# STM32WB30_CM4 register map
File version: 1.3
CPU: CM4 r0p1, little endian, MPU, FPU, 4 interrupt priority bits
Registers are 32-bit, read-write, reset 0x0 unless marked. A register's access mark holds for its fields unless they carry their own. Offsets are from the block's base; [hi:lo] are bit positions; {n}, {i} and the like mark numbered series; 'fields as' and 'values as' point back to an identical list.

## DBGMCU — Debug support
Base 0xE0042000
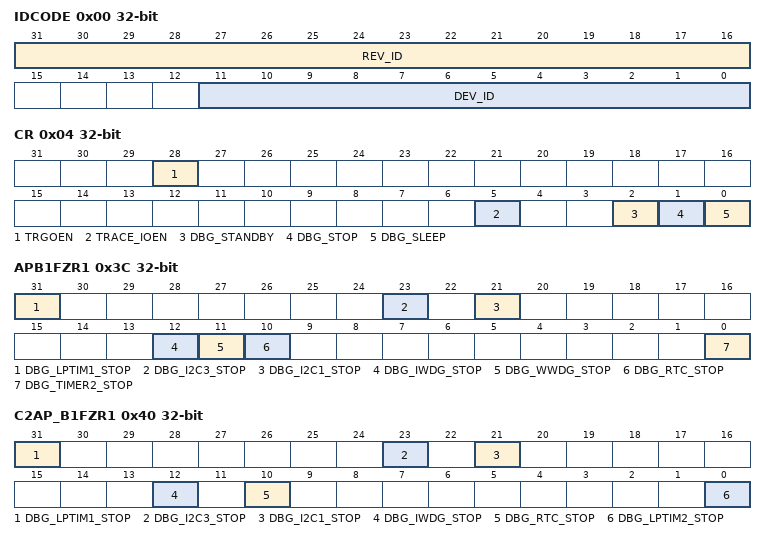
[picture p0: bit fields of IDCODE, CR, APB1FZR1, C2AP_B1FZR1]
0x00 IDCODE ro — MCU Device ID Code Register
  [31:16] REV_ID — Revision Identifier
  [11:0] DEV_ID — Device Identifier
0x04 CR — Debug MCU Configuration Register
  [28] TRGOEN — External trigger output enable
  [5] TRACE_IOEN — Trace port and clock enable
  [2] DBG_STANDBY — Debug Standby Mode
  [1] DBG_STOP — Debug Stop Mode
  [0] DBG_SLEEP — Debug Sleep Mode
0x3C APB1FZR1 — APB1 Low Freeze Register CPU1
  [31] DBG_LPTIM1_STOP — Debug LPTIM1 stopped when Core is halted
  [23] DBG_I2C3_STOP — Debug I2C3 SMBUS timeout stopped when core is halted
  [21] DBG_I2C1_STOP — Debug I2C1 SMBUS timeout stopped when Core is halted
  [12] DBG_IWDG_STOP — IWDG counter stopped when core is halted
  [11] DBG_WWDG_STOP — WWDG counter stopped when core is halted
  [10] DBG_RTC_STOP — RTC counter stopped when core is halted
  [0] DBG_TIMER2_STOP — Debug Timer 2 stopped when Core is halted
0x40 C2AP_B1FZR1 — APB1 Low Freeze Register CPU2
  [31] DBG_LPTIM1_STOP — LPTIM1 counter stopped when core is halted
  [23] DBG_I2C3_STOP — I2C3 SMBUS timeout stopped when core is halted
  [21] DBG_I2C1_STOP — I2C1 SMBUS timeout stopped when core is halted
  [12] DBG_IWDG_STOP — IWDG stopped when core is halted
  [10] DBG_RTC_STOP — RTC counter stopped when core is halted
  [0] DBG_LPTIM2_STOP — LPTIM2 counter stopped when core is halted
0x44 APB1FZR2 — APB1 High Freeze Register CPU1
  [5] DBG_LPTIM2_STOP — LPTIM2 counter stopped when core is halted
0x48 C2APB1FZR2 — APB1 High Freeze Register CPU2
  [5] DBG_LPTIM2_STOP — LPTIM2 counter stopped when core is halted
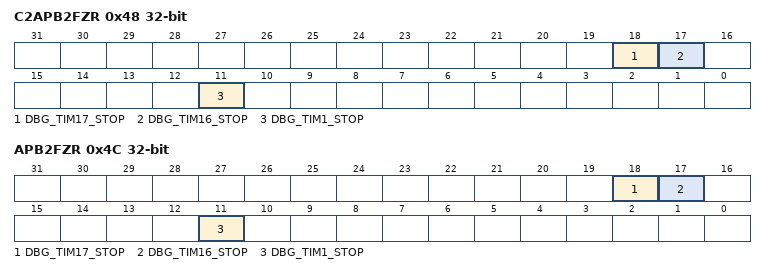
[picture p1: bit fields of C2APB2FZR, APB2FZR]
0x48 C2APB2FZR (alternate view of C2APB1FZR2) — APB2 Freeze Register CPU2
  [18] DBG_TIM17_STOP — TIM17 counter stopped when core is halted
  [17] DBG_TIM16_STOP — TIM16 counter stopped when core is halted
  [11] DBG_TIM1_STOP — TIM1 counter stopped when core is halted
0x4C APB2FZR — APB2 Freeze Register CPU1
  fields as C2APB2FZR

## PKA
Base 0x58002000
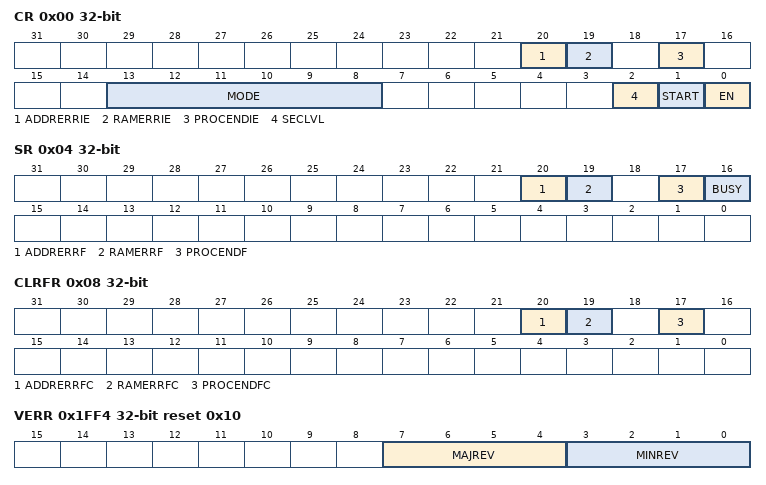
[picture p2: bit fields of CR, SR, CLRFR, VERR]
0x00 CR — Control register
  [20] ADDRERRIE — Address error interrupt enable
  [19] RAMERRIE — RAM error interrupt enable
  [17] PROCENDIE — End of operation interrupt enable
  [13:8] MODE — PKA Operation Mode
  [2] SECLVL — Security Enable
  [1] START — Start the operation
  [0] EN — Peripheral Enable
0x04 SR ro — PKA status register
  [20] ADDRERRF — Address error flag
  [19] RAMERRF — RAM error flag
  [17] PROCENDF — PKA End of Operation flag
  [16] BUSY — PKA Operation in progress
0x08 CLRFR — PKA clear flag register
  [20] ADDRERRFC — Clear Address error flag
  [19] RAMERRFC — Clear RAM error flag
  [17] PROCENDFC — Clear PKA End of Operation flag
0x1FF4 VERR ro reset 0x10 — PKA version register
  [7:4] MAJREV — Major revision
  [3:0] MINREV — Minor revision
0x1FF8 IPIDR ro reset 0x170061 — PKA identification register
  [31:0] ID — Identification Code
0x1FFC SIDR ro reset 0xA3C5DD08 — PKA size ID register
  [31:0] SID — Side Identification Code

## IPCC
Base 0x58000C00
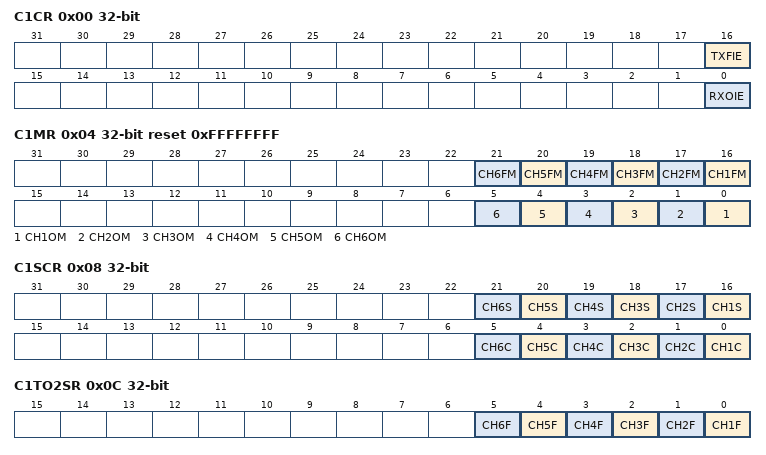
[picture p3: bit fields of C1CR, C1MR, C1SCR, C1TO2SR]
0x00 C1CR — Control register CPU1
  [16] TXFIE — processor 1 Transmit channel free interrupt enable
  [0] RXOIE — processor 1 Receive channel occupied interrupt enable
0x04 C1MR reset 0xFFFFFFFF — Mask register CPU1
  [n+15] CH{n}FM (n=1..6) — processor 1 Transmit channel {n} free interrupt mask
  [n-1] CH{n}OM (n=1..6) — processor 1 Receive channel {n} occupied interrupt enable
0x08 C1SCR wo — Status Set or Clear register CPU1
  [n+15] CH{n}S (n=1..6) — processor 1 Transmit channel {n} status set
  [n-1] CH{n}C (n=1..6) — processor 1 Receive channel {n} status clear
0x0C C1TO2SR ro — CPU1 to CPU2 status register
  [n-1] CH{n}F (n=1..6) — processor 1 transmit to process 2 Receive channel {n} status flag
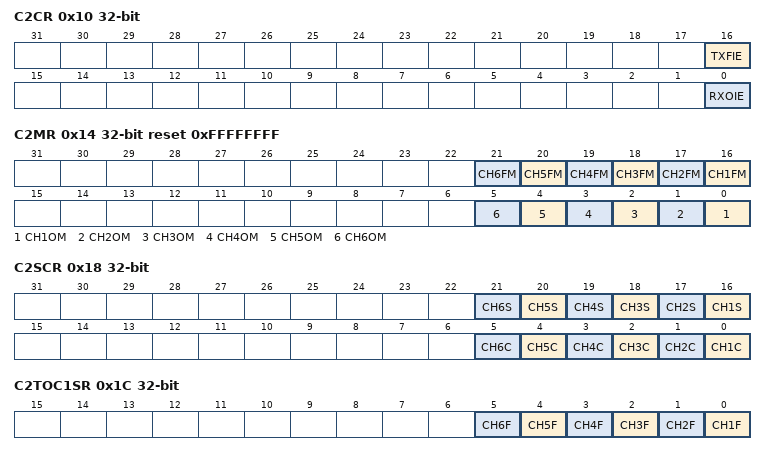
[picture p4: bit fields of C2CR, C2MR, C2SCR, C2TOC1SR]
0x10 C2CR — Control register CPU2
  [16] TXFIE — processor 2 Transmit channel free interrupt enable
  [0] RXOIE — processor 2 Receive channel occupied interrupt enable
0x14 C2MR reset 0xFFFFFFFF — Mask register CPU2
  [n+15] CH{n}FM (n=1..6) — processor 2 Transmit channel {n} free interrupt mask
  [n-1] CH{n}OM (n=1..6) — processor 2 Receive channel {n} occupied interrupt enable
0x18 C2SCR wo — Status Set or Clear register CPU2
  [n+15] CH{n}S (n=1..6) — processor 2 Transmit channel {n} status set
  [n-1] CH{n}C (n=1..6) — processor 2 Receive channel {n} status clear
0x1C C2TOC1SR ro — CPU2 to CPU1 status register
  [n-1] CH{n}F (n=1..6) — processor 2 transmit to process 1 Receive channel {n} status flag
0x3F0 HWCFGR ro reset 0x6 — IPCC Hardware configuration register
  [7:0] CHANNELS — Number of channels per CPU supported by the IP, range 1 to 16
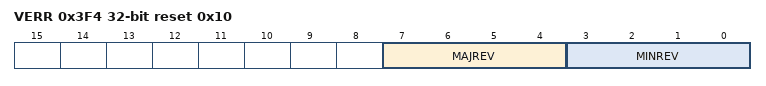
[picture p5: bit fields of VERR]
0x3F4 VERR ro reset 0x10 — IPCC version register
  [7:4] MAJREV — Major Revision
  [3:0] MINREV — Minor Revision
0x3F8 IPIDR ro reset 0x100071 — IPCC indentification register
  [31:0] IPID — Identification Code
0x3FC SIDR ro reset 0xA3C5DD01 — IPCC size indentification register
  [31:0] SID — Size Identification Code

## MPU — Memory protection unit
Base 0xE000ED90
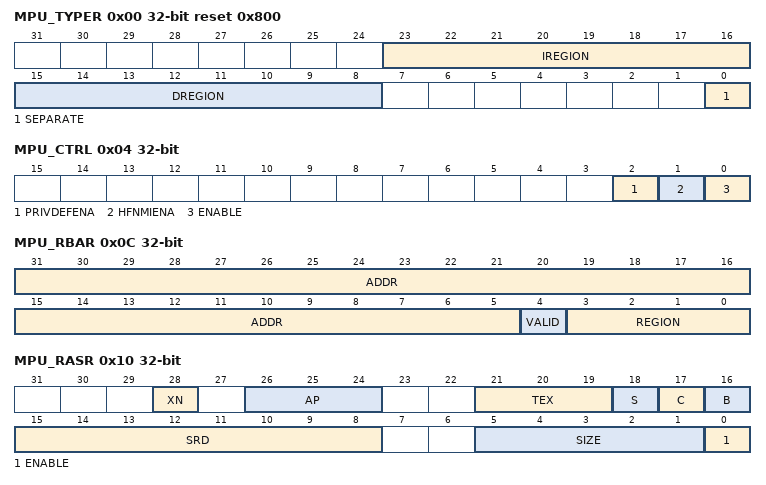
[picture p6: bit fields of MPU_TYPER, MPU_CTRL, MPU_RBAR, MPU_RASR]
0x00 MPU_TYPER ro reset 0x800 — MPU type register
  [23:16] IREGION — Number of MPU instruction regions
  [15:8] DREGION — Number of MPU data regions
  [0] SEPARATE — Separate flag
0x04 MPU_CTRL ro — MPU control register
  [2] PRIVDEFENA — Enable priviliged software access to default memory map
  [1] HFNMIENA — Enables the operation of MPU during hard fault
  [0] ENABLE — Enables the MPU
0x08 MPU_RNR — MPU region number register
  [7:0] REGION — MPU region
0x0C MPU_RBAR — MPU region base address register
  [31:5] ADDR — Region base address field
  [4] VALID — MPU region number valid
  [3:0] REGION — MPU region field
0x10 MPU_RASR — MPU region attribute and size register
  [28] XN — Instruction access disable bit
  [26:24] AP — Access permission
  [21:19] TEX — memory attribute
  [18] S — Shareable memory attribute
  [17] C — memory attribute
  [16] B — memory attribute
  [15:8] SRD — Subregion disable bits
  [5:1] SIZE — Size of the MPU protection region
  [0] ENABLE — Region enable bit.

## FPU — Floting point unit
Base 0xE000EF34
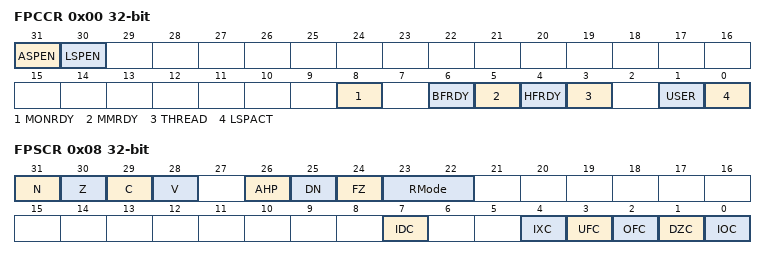
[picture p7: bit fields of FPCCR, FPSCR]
0x00 FPCCR — Floating-point context control register
  [31] ASPEN, [30] LSPEN, [8] MONRDY, [6] BFRDY, [5] MMRDY, [4] HFRDY, [3] THREAD, [1] USER, [0] LSPACT
0x04 FPCAR — Floating-point context address register
  [31:3] ADDRESS — Location of unpopulated floating-point
0x08 FPSCR — Floating-point status control register
  [31] N — Negative condition code flag
  [30] Z — Zero condition code flag
  [29] C — Carry condition code flag
  [28] V — Overflow condition code flag
  [26] AHP — Alternative half-precision control bit
  [25] DN — Default NaN mode control bit
  [24] FZ — Flush-to-zero mode control bit:
  [23:22] RMode — Rounding Mode control field
  [7] IDC — Input denormal cumulative exception bit.
  [4] IXC — Inexact cumulative exception bit
  [3] UFC — Underflow cumulative exception bit
  [2] OFC — Overflow cumulative exception bit
  [1] DZC — Division by zero cumulative exception bit.
  [0] IOC — Invalid operation cumulative exception bit

## NVIC — Nested Vectored Interrupt Controller
Base 0xE000E100
0x00 ISER0 — Interrupt Set-Enable Register
  [31:0] SETENA
0x04 ISER1 — Interrupt Set-Enable Register
  [31:0] SETENA
0x80 ICER0 — Interrupt Clear-Enable Register
  [31:0] CLRENA
0x84 ICER1 — Interrupt Clear-Enable Register
  [31:0] CLRENA
0x100 ISPR0 — Interrupt Set-Pending Register
  [31:0] SETPEND
0x104 ISPR1 — Interrupt Set-Pending Register
  [31:0] SETPEND
0x180 ICPR0 — Interrupt Clear-Pending Register
  [31:0] CLRPEND
0x184 ICPR1 — Interrupt Clear-Pending Register
  [31:0] CLRPEND
0x200 IABR0 ro — Interrupt Active Bit Register
  [31:0] ACTIVE
0x204 IABR1 ro — Interrupt Active Bit Register
  [31:0] ACTIVE
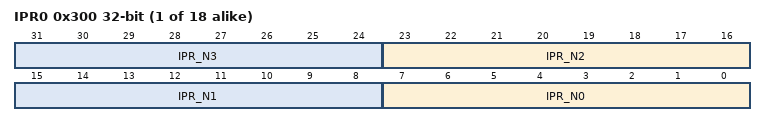
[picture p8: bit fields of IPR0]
{0x300+4i} IPR{i} (i=0..17) — Interrupt Priority Register
  [8n+7:8n] IPR_N{n} (n=0..3)

## NVIC_STIR — Nested vectored interrupt controller
Base 0xE000EF00
0x00 STIR — Software trigger interrupt register
  [8:0] INTID — Software generated interrupt ID

## SCB_ACTRL — System control block ACTLR
Base 0xE000E008
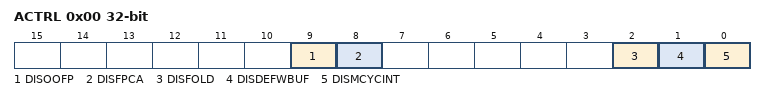
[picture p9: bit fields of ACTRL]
0x00 ACTRL — Auxiliary control register
  [9] DISOOFP, [8] DISFPCA, [2] DISFOLD, [1] DISDEFWBUF, [0] DISMCYCINT

## FPU_CPACR — Floating point unit CPACR
Base 0xE000ED88
0x00 CPACR — Coprocessor access control register
  [23:20] CP
